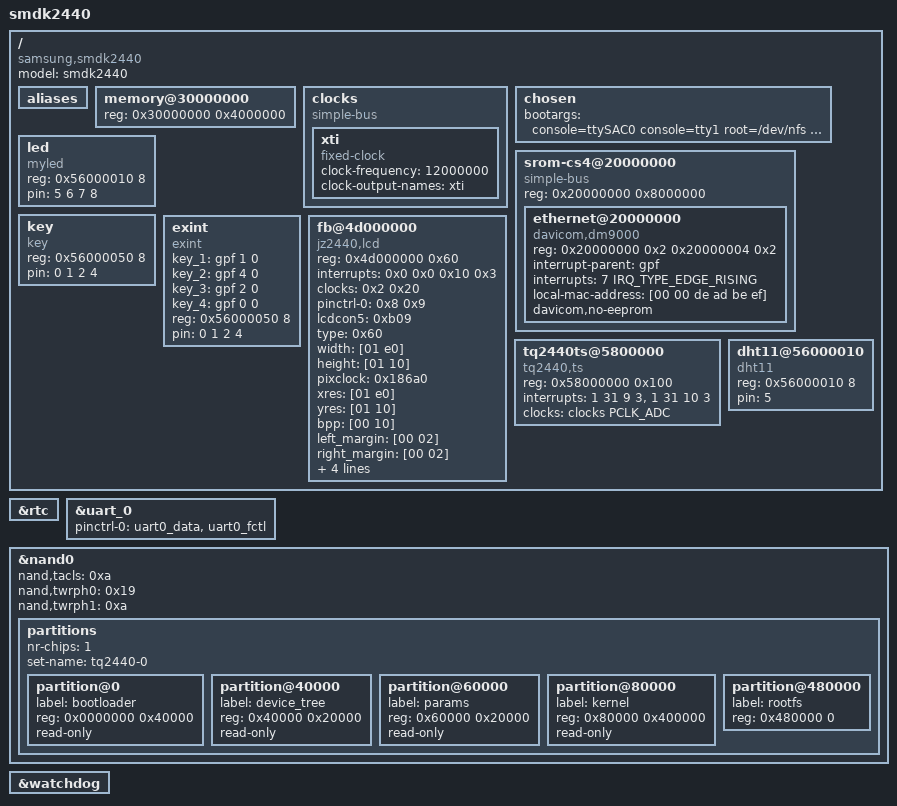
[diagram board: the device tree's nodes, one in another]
// SPDX-License-Identifier: GPL-2.0
/*
 * SAMSUNG SMDK2416 board device tree source
 *
 * Copyright (c) 2013 Heiko Stuebner <heiko@sntech.de>
 */

/dts-v1/;
#include "s3c2440.dtsi"
#include "/home/zhoubo/desktop/Linux内核移植/tq2440/linux-4.19-rc3/include/dt-bindings/interrupt-controller/irq.h"


/ {
	model = "smdk2440";
	compatible = "samsung,smdk2440";

	aliases {
	//	i2c1 = &i2c_gpio_1;
	}; 

	memory@30000000 {
		device_type = "memory";
		reg =  <0x30000000 0x4000000>;
	};
	clocks {
		compatible = "simple-bus";
		xti: xti {
			compatible = "fixed-clock";
			clock-frequency = <12000000>;
			clock-output-names = "xti";
			#clock-cells = <0>;
		};
	};
	
	chosen {
		//for tq2440
		//nfs启动
		bootargs = "console=ttySAC0 console=tty1 root=/dev/nfs rw nfsroot=192.168.1.8:/work/nfs_4.19-rc3 ip=192.168.1.6:192.168.1.8:192.168.1.6:255.255.255.0:SKY2440.embedsky.net:eth0:off";
		//yaffs2启动
		//bootargs = "noinitrd root=/dev/mtdblock4 rw init=/linuxrc console=ttySAC0,115200";                  
	};
//for dm9000
	srom-cs4@20000000 {
		compatible = "simple-bus";
		#address-cells = <1>;
		#size-cells = <1>;
		reg = <0x20000000 0x8000000>;
		ranges;
							
		ethernet@20000000 {
			compatible = "davicom,dm9000";
			reg = <0x20000000 0x2 0x20000004 0x2>;
			interrupt-parent = <&gpf>;
			interrupts = <7 IRQ_TYPE_EDGE_RISING>;
			local-mac-address = [00 00 de ad be ef];
			davicom,no-eeprom;
		};
	};
	led {
		compatible = "myled";
		reg = <0x56000010 8>;
		pin = <5 6 7 8>;
	};

	key {
		compatible = "key";
		reg = <0x56000050 8>;
		pin = <0 1 2 4>;
	};

	//外部中断
	exint {
        compatible = "exint";
		//博客园"摩斯电码"写的
/*
        interrupt-parent = <&gpf>;
		interrupts = <0 IRQ_TYPE_EDGE_FALLING>, <1 IRQ_TYPE_EDGE_FALLING>;
        key_3 = <&gpf 2 0>;
		key_4 = <&gpf 4 0>;
		key_8 = <&gpg 0 0>;
*/
		
		//方法1:要与驱动中exint_probe()的方法1对应
		key_1 = <&gpf 1 0>;
		key_2 = <&gpf 4 0>;
		key_3 = <&gpf 2 0>;
		key_4 = <&gpf 0 0>;
		
		/*
		//或者
		//方法2:要与驱动中exint_probe()的方法2对应
        interrupt-parent = <&gpf>;
		interrupts = <1 IRQ_TYPE_EDGE_FALLING>, <4 IRQ_TYPE_EDGE_FALLING>,
					 <2 IRQ_TYPE_EDGE_FALLING>, <0 IRQ_TYPE_EDGE_FALLING>;
		*/
		reg = <0x56000050 8>;
		pin = <0 1 2 4>;
    };

	//for lcd
	fb@4d000000 {
		compatible = "jz2440,lcd";
		reg = <0x4d000000 0x60>;
		interrupts = <0x0 0x0 0x10 0x3>;
		clocks = <0x2 0x20>;
		clock-names = "lcd";
		pinctrl-names = "default";
		pinctrl-0 = <0x8 0x9>;
		status = "okay";
		lcdcon5 = <0xb09>;
		type = <0x60>;
		width = [01 e0];
		height = [01 10];
		pixclock = <0x186a0>;
		xres = [01 e0];
		yres = [01 10];
		bpp = [00 10];
		left_margin = [00 02];
		right_margin = [00 02];
		hsync_len = [00 29];
		upper_margin = [00 02];
		lower_margin = [00 02];
		vsync_len = [00 0a];
	};
	
	//for touchscreen
	tq2440ts@5800000 {
		compatible = "tq2440,ts";
		reg = <0x58000000 0x100>;
		reg-names = "adc_ts_physical";
		interrupts = <1 31 9 3>, <1 31 10 3>;
		interrupt-names = "int_ts", "int_adc_s";
		clocks = <&clocks PCLK_ADC>;
		clock-names = "adc";
	};		

	dht11@56000010 {
		compatible = "dht11";
		reg-names =	"gpbcon"; 
		reg = <0x56000010 8>;
		pin = <5>;
	};

};
&rtc {
	status = "okay";
};
/*
&sdhci_0 {
	pinctrl-names = "default";
	pinctrl-0 = <&sd1_clk>, <&sd1_cmd>,
			<&sd1_bus1>, <&sd1_bus4>;
	bus-width = <4>;
	broken-cd;
	status = "okay";
};

&sdhci_1 {
	pinctrl-names = "default";
	pinctrl-0 = <&sd0_clk>, <&sd0_cmd>,
			<&sd0_bus1>, <&sd0_bus4>;
	bus-width = <4>;
	cd-gpios = <&gpf 1 0>;
	cd-inverted;
	status = "okay";
};
*/
&uart_0 {
	status = "okay";
	pinctrl-names = "default";
	pinctrl-0 = <&uart0_data>, <&uart0_fctl>;
};

&nand0 {
	status = "okay";
	nand,tacls = <0xa>;
	nand,twrph0 = <0x19>;
	nand,twrph1 = <0xa>;

	#address-cells = <1>;
	#size-cells = <1>;

	partitions {
		/* MTD partition table */
		#address-cells = <1>;
		#size-cells = <1>;
		nr-chips = <1>;
		set-name = "tq2440-0";

		partition@0 {
			label = "bootloader";
			reg = <0x0000000 0x40000>;
			read-only;
		};

		partition@40000 {
			label = "device_tree";
			reg = <0x40000 0x20000>;
			read-only;
		};

		partition@60000 {
			label = "params";
			reg = <0x60000 0x20000>;
			read-only;
		};

		partition@80000 {
			label = "kernel";
			reg = <0x80000 0x400000>;
			read-only;
		};

		partition@480000 {
			label = "rootfs";
			reg = <0x480000 0>;
		};
	};
};

/*
&uart_1 {
	status = "okay";
	pinctrl-names = "default";
	pinctrl-0 = <&uart1_data>, <&uart1_fctl>;
};

&uart_2 {
	status = "okay";
	pinctrl-names = "default";
	pinctrl-0 = <&uart2_data>;
};

&uart_3 {
	status = "okay";
	pinctrl-names = "default";
	pinctrl-0 = <&uart3_data>;
};
*/
&watchdog {
	status = "okay";
};
